# VPAC0_COMMON_0_IVPAC_TOP_0_CFG_SLV_PAR_VPAC_LDC0_S_VBUSP_VPAC_LDC_LSE_CFG_VP register map
Vendor: Texas Instruments
Peripheral module from a debugger description file (folder am62A).
Registers are 32-bit, read-only, reset values left out (the file's numbers can be read two ways) unless marked. A register's access mark holds for its fields unless they carry their own. Offsets are as the file gives them; lines under a group give offsets from that group; [hi:lo] are bit positions; {n}, {i} and the like mark numbered series; 'fields as' and 'values as' point back to an identical list; <NAME> marks a mode.

## VPAC0_COMMON_0_IVPAC_TOP_0_CFG_SLV_PAR_VPAC_LDC0_S_VBUSP_VPAC_LDC_LSE_CFG_VP
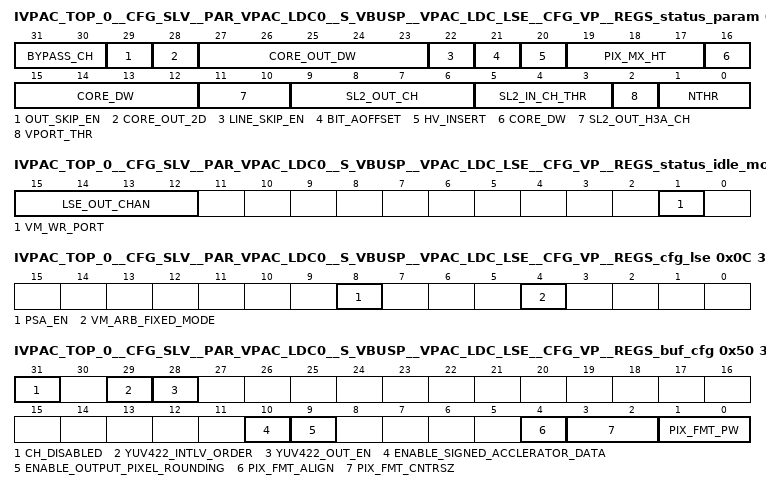
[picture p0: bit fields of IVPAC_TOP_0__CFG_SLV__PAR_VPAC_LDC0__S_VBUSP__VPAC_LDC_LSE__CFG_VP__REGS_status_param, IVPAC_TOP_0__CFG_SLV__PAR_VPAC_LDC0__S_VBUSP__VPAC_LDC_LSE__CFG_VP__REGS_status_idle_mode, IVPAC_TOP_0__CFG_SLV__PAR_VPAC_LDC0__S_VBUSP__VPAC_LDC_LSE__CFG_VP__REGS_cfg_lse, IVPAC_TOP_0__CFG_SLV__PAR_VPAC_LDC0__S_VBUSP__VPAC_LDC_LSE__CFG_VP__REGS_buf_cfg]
0x00 IVPAC_TOP_0__CFG_SLV__PAR_VPAC_LDC0__S_VBUSP__VPAC_LDC_LSE__CFG_VP__REGS_status_param — The STATUS_PARAM register returns the LSE compile configuration parameters.
  [31:30] BYPASS_CH — Number of available input channel selection for loopback mode
  [29] OUT_SKIP_EN — Output Auto-Skip Enable
  [28] CORE_OUT_2D — 1D or 2D output addressing mode(2D if 1)
  [27:23] CORE_OUT_DW — Core Output Channel Data Width
  [22] LINE_SKIP_EN — Source Line Inc by 2 Supported (if 1)
  [21] BIT_AOFFSET — Source nibble offset address Supported (if 1)
  [20] HV_INSERT — H/VBLANK Insertion Supported (if 1)
  [19:17] PIX_MX_HT — Core_Input Pixel Matrix Height
  [16:12] CORE_DW — Core Input Data Bus Width
  [11:10] SL2_OUT_H3A_CH — Number of SL2 H3A Output Channels
  [9:6] SL2_OUT_CH — Number of SL2 Output Channels
  [5:3] SL2_IN_CH_THR — Number of Input Channels per thread
  [2] VPORT_THR — Number of VPORT input enabled
  [1:0] NTHR — Number of threads supported
0x04 IVPAC_TOP_0__CFG_SLV__PAR_VPAC_LDC0__S_VBUSP__VPAC_LDC_LSE__CFG_VP__REGS_status_error access not given — The STATUS_ERROR register returns the LSE error status.
  [14:8] VM_WR_ERR — VBUSM I/F Last Write Error Status [14:11] Write Channel Number [10:8] VBUSM write error status (access R/W1TC)
0x08 IVPAC_TOP_0__CFG_SLV__PAR_VPAC_LDC0__S_VBUSP__VPAC_LDC_LSE__CFG_VP__REGS_status_idle_mode — The STATUS_IDLE_MODE register returns IDLE status of LSE VBUSM port and in/output channels - 0: IDLE 1: ACTIVE
  [15:12] LSE_OUT_CHAN — Output Channel[3:0] Status
  [1] VM_WR_PORT — SL2 vbusm I/F Write Port Status
0x0C IVPAC_TOP_0__CFG_SLV__PAR_VPAC_LDC0__S_VBUSP__VPAC_LDC_LSE__CFG_VP__REGS_cfg_lse rw — The CFG_LSE register configures the LSE general hardware modes.
  [8] PSA_EN — Test mode Output Channel Signature Generation Enable 0: Disable (default) 1: Enable When enabled, LSE generates a unique CRC signature for each output channel's frame data at frame completion.
  [4] VM_ARB_FIXED_MODE — VBUSM Arbitration Fixed Mode select 0: Round-Robin Arbitration (default) 1: Fixed-mode Arbitration
0x50 IVPAC_TOP_0__CFG_SLV__PAR_VPAC_LDC0__S_VBUSP__VPAC_LDC_LSE__CFG_VP__REGS_buf_cfg access per field — The DST_BUF_CFG register configures the output buffer channel .
  [31] CH_DISABLED ro — Channel Disable Status (read-only) 0: (Default) Chanel is enabled for Y, UV or YUV422 data transfer to SL2 memory. All configurations associated with this DST_BUF[a] are valid. 1: Channel is disabled for SL2 data transfer (because the channel logic is used internally for YUV data interleaving). All configuration associated with this DST_BUF[a] are ignored.
  [29] YUV422_INTLV_ORDER rw — YUV422 Interleaving Order Selection 0: UYVY 1: YUYV Only Applicable if this output channel is YUV422 output capable LUMA channel. Otherwise, setting has no effect.
  [28] YUV422_OUT_EN rw — YUV422 Interleaved Output Merge Enable 0: Disable 1: Enable When enabled, this channel interleaves data from the associated chroma data output channel to output YUV422 interleaved data to the SL2 memory. Only Applicable if this output channel is YUV422 output capable LUMA channel. Otherwise, setting has no effect.
  [10] ENABLE_SIGNED_ACCLERATOR_DATA rw — Specify the acclerator data to be signed or unsigned 0: Unsigned data (By default) 1: Signed Data
  [9] ENABLE_OUTPUT_PIXEL_ROUNDING rw — enable acclerator pixel output rounding 0: Disable rounding logic 1: Enable rounding logic
  [4] PIX_FMT_ALIGN rw — Output Pixel Container Alignment 0: LSB-aligned 1: MSB-aligned
  [3:2] PIX_FMT_CNTRSZ rw — Output Pixel Container Size Sel 0: 8-bit 1: 12-bit 2: 16-bit 3: reserved Output pixel container size must be same or larger than output pixel width. If yuv422_out_en is set, pix_fmt_cntrsz must be 0.
  [1:0] PIX_FMT_PW rw — Output Pixel Width Sel 0: 8-bit 1: 12-bit 2: reserved 3: 16-bit The width defines the bit-depth of the pixel data to be stored in the pixel container.
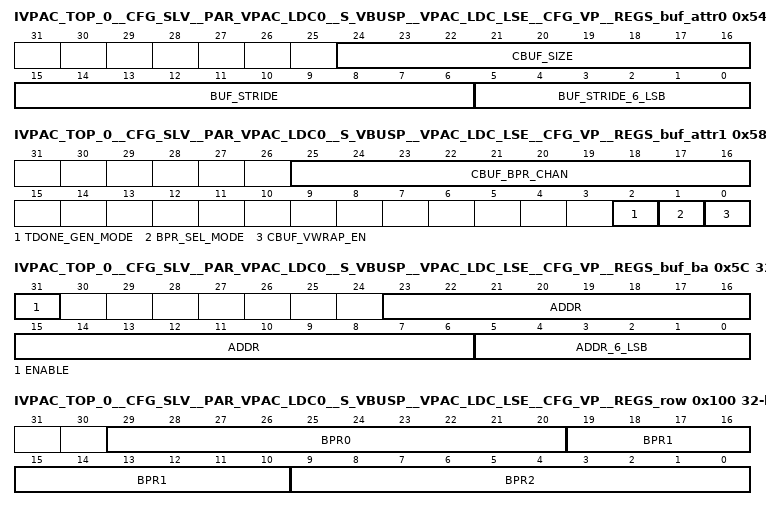
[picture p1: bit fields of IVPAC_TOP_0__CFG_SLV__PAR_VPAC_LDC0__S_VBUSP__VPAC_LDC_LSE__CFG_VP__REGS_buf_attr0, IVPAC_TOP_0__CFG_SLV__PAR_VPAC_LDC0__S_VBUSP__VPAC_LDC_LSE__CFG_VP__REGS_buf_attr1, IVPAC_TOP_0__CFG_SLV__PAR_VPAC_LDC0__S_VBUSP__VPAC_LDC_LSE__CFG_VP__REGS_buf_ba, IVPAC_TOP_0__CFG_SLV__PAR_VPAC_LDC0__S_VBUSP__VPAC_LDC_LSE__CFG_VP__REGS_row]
0x54 IVPAC_TOP_0__CFG_SLV__PAR_VPAC_LDC0__S_VBUSP__VPAC_LDC_LSE__CFG_VP__REGS_buf_attr0 access per field — The DST_BUF_ATTR0 register configures the attributes of the output SL2 buffer .
  [24:16] CBUF_SIZE rw — SL2 Circular Buffer Size (number of line buffers)
  [15:6] BUF_STRIDE rw — Buffer Stride Size [15:6] (64 byte multiple) stride size
  [5:0] BUF_STRIDE_6_LSB ro — Buffer Stride Size [5:0] - 6 LSB bits of buffer stride size should always be 0. Writes have no effect. Always read as 0
0x58 IVPAC_TOP_0__CFG_SLV__PAR_VPAC_LDC0__S_VBUSP__VPAC_LDC_LSE__CFG_VP__REGS_buf_attr1 rw — The DST_BUF_ATTR1 register configures the 2D Block attributes of the output SL2 buffer .
  [25:16] CBUF_BPR_CHAN — Circular Buffer - 2D blocks per row defined by cbuf_stride (selected when bpr_sel_mode=0)
  [2] TDONE_GEN_MODE — HTS Tdone Generation Mode for 2D transfer 0: Generate Tdone on every 2D block completion 1: Generate Tdone only at the end of CBUF_BPR Must be common across all DST channels and Must be set to 0 when BPR settings for enabled output channels are different.
  [1] BPR_SEL_MODE — CBUF BPR Selection mode 0: Use cbuf_bpr_chan (applied to all regions) for this output channel 1: Use the common multi-region BPR parameters
  [0] CBUF_VWRAP_EN — CBUF Vertical Wrap Enable 0: Disable (for Memory to Memory data transfer mode) 1: Enable (for In-Line Rasterization Mode)
0x5C IVPAC_TOP_0__CFG_SLV__PAR_VPAC_LDC0__S_VBUSP__VPAC_LDC_LSE__CFG_VP__REGS_buf_ba access per field — The DST_BUF_BA register configures the base address of the output SL2 circular buffer .
  [31] ENABLE rw — Output Channel Enable 0: Disable 1: Enable
  [23:6] ADDR rw — Base Address[23:6] - (64 Byte aligned) byte address
  [5:0] ADDR_6_LSB ro — Base Address[5:0] - 6 LSB bits of address should always be 0. Writes have no effect. Always read as 0
0x100 IVPAC_TOP_0__CFG_SLV__PAR_VPAC_LDC0__S_VBUSP__VPAC_LDC_LSE__CFG_VP__REGS_row rw — The COMMON_CFG_ROW registers configure the common CBUF_BPR values for regions of all output channels.
  [29:20] BPR0 — Region [a,0] CBUF_BPR value
  [19:10] BPR1 — Region [a,1] CBUF_BPR value
  [9:0] BPR2 — Region [a,2] CBUF_BPR value
0x13C IVPAC_TOP_0__CFG_SLV__PAR_VPAC_LDC0__S_VBUSP__VPAC_LDC_LSE__CFG_VP__REGS_dst_common_cfg rw — The DST_COMMON_CFG register captures common configuration for the output channels
  [5:0] ROUNDING_OFFSET — output channel rounding offset value. Default value to be considered 6'h08
0x140 IVPAC_TOP_0__CFG_SLV__PAR_VPAC_LDC0__S_VBUSP__VPAC_LDC_LSE__CFG_VP__REGS_psa_signature — The PSA_SIGNATURE register returns the captured PSA signature value of the last frame data of output channel [a].
  [31:0] VALUE — 32-bit CRC signature value
0x1E0 IVPAC_TOP_0__CFG_SLV__PAR_VPAC_LDC0__S_VBUSP__VPAC_LDC_LSE__CFG_VP__REGS_dbg — The DBG register returns the current status of internal FSM - TI internal use only.
  [31:0] STATUS — Debug status
